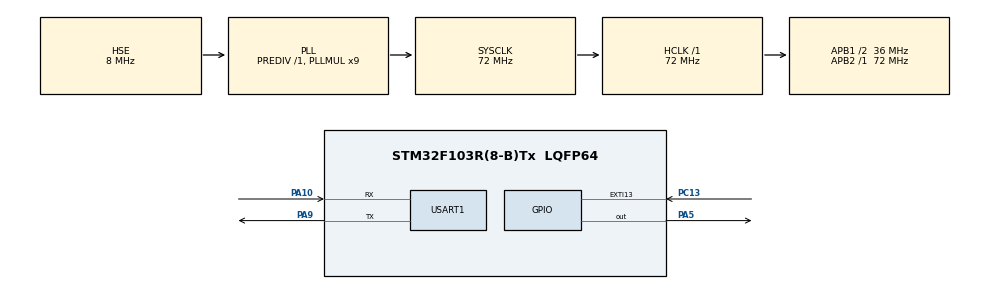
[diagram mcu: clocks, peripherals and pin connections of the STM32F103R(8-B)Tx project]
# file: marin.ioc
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FREERTOS.Tasks01=defaultTask,24,128,StartDefaultTask,Default,NULL,Dynamic,NULL,NULL
Mcu.Family=STM32F1
Mcu.Name=STM32F103R(8-B)Tx
Mcu.Package=LQFP64
NVIC.EXTI15_10_IRQn=true\:5\:0\:false\:false\:true\:true\:true\:true\:true
NVIC.PriorityGroup=NVIC_PRIORITYGROUP_4
NVIC.TIM4_IRQn=true\:15\:0\:false\:false\:true\:false\:false\:true\:true
NVIC.TimeBase=TIM4_IRQn
NVIC.TimeBaseIP=TIM4
NVIC.USART1_IRQn=true\:5\:0\:false\:false\:true\:true\:true\:true\:true
PA10.Mode=Asynchronous
PA10.Signal=USART1_RX
PA11.Signal=S_TIM1_CH4
PA13.Mode=Serial_Wire
PA13.Signal=SYS_JTMS-SWDIO
PA14.Mode=Serial_Wire
PA14.Signal=SYS_JTCK-SWCLK
PA2.Signal=USART2_TX
PA3.Signal=USART2_RX
PA5.Signal=GPIO_Output
PA8.Signal=S_TIM1_CH1
PA9.Mode=Asynchronous
PA9.Signal=USART1_TX
PC13-TAMPER-RTC.Signal=GPXTI13
PD0-OSC_IN.Mode=HSE-External-Oscillator
PD0-OSC_IN.Signal=RCC_OSC_IN
PD1-OSC_OUT.Mode=HSE-External-Oscillator
PD1-OSC_OUT.Signal=RCC_OSC_OUT
ProjectManager.HeapSize=0x200
ProjectManager.StackSize=0x400
ProjectManager.TargetToolchain=STM32CubeIDE
RCC.AHBFreq_Value=72000000
RCC.APB1CLKDivider=RCC_HCLK_DIV2
RCC.APB1Freq_Value=36000000
RCC.APB1TimFreq_Value=72000000
RCC.APB2Freq_Value=72000000
RCC.APB2TimFreq_Value=72000000
RCC.HCLKFreq_Value=72000000
RCC.PLLMUL=RCC_PLL_MUL9
RCC.PLLSourceVirtual=RCC_PLLSOURCE_HSE
RCC.SYSCLKFreq_VALUE=72000000
RCC.SYSCLKSource=RCC_SYSCLKSOURCE_PLLCLK
RCC.USBFreq_Value=72000000
SH.S_TIM1_CH1.0=TIM1_CH1
SH.S_TIM1_CH4.0=TIM1_CH4
USART1.VirtualMode=VM_ASYNC
VP_FREERTOS_VS_CMSIS_V2.Mode=CMSIS_V2
VP_SYS_VS_tim4.Mode=TIM4
board=custom

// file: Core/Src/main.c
/* USER CODE BEGIN Header */
/**
  ******************************************************************************
  * @file           : main.c
  * @brief          : Main program body
  ******************************************************************************
  * @attention
  *
  * Copyright (c) 2022 STMicroelectronics.
  * All rights reserved.
  *
  * This software is licensed under terms that can be found in the LICENSE file
  * in the root directory of this software component.
  * If no LICENSE file comes with this software, it is provided AS-IS.
  *
  ******************************************************************************
  */
/* USER CODE END Header */
#include "main.h"
#include "cmsis_os.h"
#include "ring.c"

UART_HandleTypeDef huart1;

/* Definitions for defaultTask */
osThreadId_t defaultTaskHandle;
const osThreadAttr_t defaultTask_attributes = {
  .name = "defaultTask",
  .stack_size = 128 * 4,
  .priority = (osPriority_t) osPriorityNormal,
};
const osThreadAttr_t RecvTask_attributes = {
  .name = "Recv Task",
  .stack_size = 128 * 4,
  .priority = (osPriority_t) osPriorityNormal,
};

void SystemClock_Config(void);
static void MX_GPIO_Init(void);
static void MX_USART1_UART_Init(void);
void StartDefaultTask(void *argument);
void StartRecvTask(void *argument);

int main(void)
{
  /* USER CODE BEGIN 1 */
	uint8_t data;
	rb rbdata;
	rb* ptrbdata;
  /* USER CODE END 1 */

  /* MCU Configuration--------------------------------------------------------*/

  /* Reset of all peripherals, Initializes the Flash interface and the Systick. */
  HAL_Init();

  /* Configure the system clock */
  SystemClock_Config();

  /* Initialize all configured peripherals */
  MX_GPIO_Init();
  MX_USART1_UART_Init();
  /* USER CODE BEGIN 2 */
  HAL_UART_Receive_IT(&huart1, &data, 1); // ready to get data

  /* USER CODE END 2 */

  /* Init scheduler */
  osKernelInitialize();

  /* Create the thread(s) */
  /* creation of defaultTask */
  defaultTaskHandle = osThreadNew(StartDefaultTask, NULL, &defaultTask_attributes);

  recvTaskHandle = osThreadNew(RecvDefaultTask, NULL, &RecvTask_attributes);

  /* Start scheduler */
  osKernelStart();

  /* We should never get here as control is now taken by the scheduler */
  /* Infinite loop */
  /* USER CODE BEGIN WHILE */
  while (1)
  {

   }
	  /*
	  HAL_GPIO_WritePin(GPIOB, GPIO_Pin_6, GPIO_PIN_SET);
	  HAL_Delay(Delay);
	  HAL_GPIO_WritePin(GPIOB, GPIO_Pin_6, GPIO_PIN_RESET);
	  HAL_Delay(Delay);
	  PB. 6. pin control, set reset*/
    /* USER CODE END WHILE */

  }
}

void SystemClock_Config(void)
{
  RCC_OscInitTypeDef RCC_OscInitStruct = {0};
  RCC_ClkInitTypeDef RCC_ClkInitStruct = {0};

  /** Initializes the RCC Oscillators according to the specified parameters
  * in the RCC_OscInitTypeDef structure.
  */
  RCC_OscInitStruct.OscillatorType = RCC_OSCILLATORTYPE_HSE;
  RCC_OscInitStruct.HSEState = RCC_HSE_ON;
  RCC_OscInitStruct.HSEPredivValue = RCC_HSE_PREDIV_DIV1;
  RCC_OscInitStruct.HSIState = RCC_HSI_ON;
  RCC_OscInitStruct.PLL.PLLState = RCC_PLL_ON;
  RCC_OscInitStruct.PLL.PLLSource = RCC_PLLSOURCE_HSE;
  RCC_OscInitStruct.PLL.PLLMUL = RCC_PLL_MUL9;
  if (HAL_RCC_OscConfig(&RCC_OscInitStruct) != HAL_OK)
  {
    Error_Handler();
  }

  /** Initializes the CPU, AHB and APB buses clocks
  */
  RCC_ClkInitStruct.ClockType = RCC_CLOCKTYPE_HCLK|RCC_CLOCKTYPE_SYSCLK
                              |RCC_CLOCKTYPE_PCLK1|RCC_CLOCKTYPE_PCLK2;
  RCC_ClkInitStruct.SYSCLKSource = RCC_SYSCLKSOURCE_PLLCLK;
  RCC_ClkInitStruct.AHBCLKDivider = RCC_SYSCLK_DIV1;
  RCC_ClkInitStruct.APB1CLKDivider = RCC_HCLK_DIV2;
  RCC_ClkInitStruct.APB2CLKDivider = RCC_HCLK_DIV1;

  if (HAL_RCC_ClockConfig(&RCC_ClkInitStruct, FLASH_LATENCY_2) != HAL_OK)
  {
    Error_Handler();
  }
}

static void MX_USART1_UART_Init(void)
{

  huart1.Instance = USART1;
  huart1.Init.BaudRate = 115200;
  huart1.Init.WordLength = UART_WORDLENGTH_8B;
  huart1.Init.StopBits = UART_STOPBITS_1;
  huart1.Init.Parity = UART_PARITY_NONE;
  huart1.Init.Mode = UART_MODE_TX_RX;
  huart1.Init.HwFlowCtl = UART_HWCONTROL_NONE;
  huart1.Init.OverSampling = UART_OVERSAMPLING_16;
  if (HAL_UART_Init(&huart1) != HAL_OK)
  {
    Error_Handler();
  }

}

static void MX_GPIO_Init(void)
{
  GPIO_InitTypeDef GPIO_InitStruct = {0};

  /* GPIO Ports Clock Enable */
  __HAL_RCC_GPIOC_CLK_ENABLE();
  __HAL_RCC_GPIOD_CLK_ENABLE();
  __HAL_RCC_GPIOA_CLK_ENABLE();

  /*Configure GPIO pin Output Level */
  HAL_GPIO_WritePin(GPIOA, GPIO_PIN_5, GPIO_PIN_RESET);

  /*Configure GPIO pin : PC13 */
  GPIO_InitStruct.Pin = GPIO_PIN_13;
  GPIO_InitStruct.Mode = GPIO_MODE_IT_RISING;
  GPIO_InitStruct.Pull = GPIO_NOPULL;
  HAL_GPIO_Init(GPIOC, &GPIO_InitStruct);

  /*Configure GPIO pin : PA2 */
  GPIO_InitStruct.Pin = GPIO_PIN_2;
  GPIO_InitStruct.Mode = GPIO_MODE_AF_PP;
  GPIO_InitStruct.Speed = GPIO_SPEED_FREQ_HIGH;
  HAL_GPIO_Init(GPIOA, &GPIO_InitStruct);

  /*Configure GPIO pin : PA3 */
  GPIO_InitStruct.Pin = GPIO_PIN_3;
  GPIO_InitStruct.Mode = GPIO_MODE_INPUT;
  GPIO_InitStruct.Pull = GPIO_NOPULL;
  HAL_GPIO_Init(GPIOA, &GPIO_InitStruct);

  /*Configure GPIO pin : PA5 */
  GPIO_InitStruct.Pin = GPIO_PIN_5;
  GPIO_InitStruct.Mode = GPIO_MODE_OUTPUT_PP;
  GPIO_InitStruct.Pull = GPIO_NOPULL;
  GPIO_InitStruct.Speed = GPIO_SPEED_FREQ_LOW;
  HAL_GPIO_Init(GPIOA, &GPIO_InitStruct);

  /*Configure GPIO pins : PA8 PA11 */
  GPIO_InitStruct.Pin = GPIO_PIN_8|GPIO_PIN_11;
  GPIO_InitStruct.Mode = GPIO_MODE_AF_PP;
  GPIO_InitStruct.Speed = GPIO_SPEED_FREQ_LOW;
  HAL_GPIO_Init(GPIOA, &GPIO_InitStruct);

  /* EXTI interrupt init*/
  HAL_NVIC_SetPriority(EXTI15_10_IRQn, 5, 0);
  HAL_NVIC_EnableIRQ(EXTI15_10_IRQn);

}

void StartRecvTask(void *argument)
{
  for(;;)
  {
    osDelay(1);
  }
}

void StartDefaultTask(void *argument)
{
	rb rbdata;
	rb* ptrbdata;
  while(1)
  {
   HAL_UART_Receive_IT(&huart1, ptrbdata, 1); // ready to get data
    osDelay(1);//단위 ms
  }
  /* USER CODE END 5 */
}

void HAL_TIM_PeriodElapsedCallback(TIM_HandleTypeDef *htim)
{
  if (htim->Instance == TIM4) {
    HAL_IncTick();
  }
}

void Error_Handler(void)
{
  __disable_irq();
  while (1)
  {
  }
}
